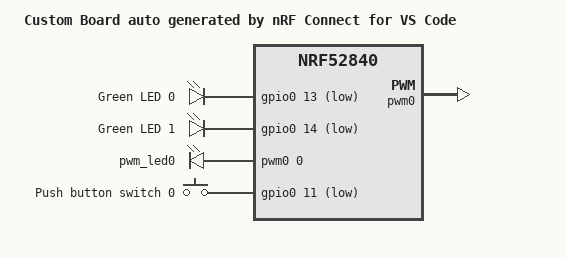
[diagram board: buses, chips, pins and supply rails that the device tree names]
/dts-v1/;
#include <nordic/nrf52840_qiaa.dtsi>
#include "custom_nrf52840_dk-pinctrl.dtsi"

/ {
	model = "Custom Board auto generated by nRF Connect for VS Code";
	compatible = "nordic_semiconductor,custom-nrf52840-dk";

	chosen {
		zephyr,sram = &sram0;
		zephyr,flash = &flash0;
		zephyr,code-partition = &slot0_partition;
	};

	leds {
		compatible = "gpio-leds";
		led0: led_0 {
			gpios = <&gpio0 13 GPIO_ACTIVE_LOW>;
			label = "Green LED 0";
		};

		led1: led_1 {
			gpios = <&gpio0 14 GPIO_ACTIVE_LOW>;
			label = "Green LED 1";
		};

	};
	
	pwmleds {
		compatible = "pwm-leds";
		pwm_led0: pwm_led_0 {
			pwms = <&pwm0 0 PWM_MSEC(20) PWM_POLARITY_INVERTED>;
		};
	};
	
	buttons {
		compatible = "gpio-keys";
		button0: button_0 {
			gpios = <&gpio0 11 (GPIO_PULL_UP | GPIO_ACTIVE_LOW)>;
			label = " Push button switch 0";
		};
	};
	
	aliases {
		led0 = &led0;
		led1 = &led1;
		sw0 = &button0;
		pwmled0 = &pwm_led0;
	};

};

&flash0 {
	partitions {
		compatible = "fixed-partitions";
		#address-cells = <1>;
		#size-cells = <1>;

		boot_partition: partition@0 {
			label = "mcuboot";
			reg = <0x00000000 DT_SIZE_K(48)>;
		};

		slot0_partition: partition@c000 {
			label = "image-0";
			reg = <0x0000c000 DT_SIZE_K(412)>;
		};

		slot1_partition: partition@73000 {
			label = "image-1";
			reg = <0x00073000 DT_SIZE_K(412)>;
		};

		scratch_partition: partition@da000 {
			label = "image-scratch";
			reg = <0xda000 DT_SIZE_K(120)>;
		};

		storage_partition: partition@f8000 {
			label = "storage";
			reg = <0x000f8000 DT_SIZE_K(32)>;
		};
	};

};

&gpio0 {
	status = "okay";
};

&pwm0 {
	status = "okay";
	pinctrl-0 = <&pwm0_default>;
	pinctrl-1 = <&pwm0_sleep>;
	pinctrl-names = "default", "sleep";
};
